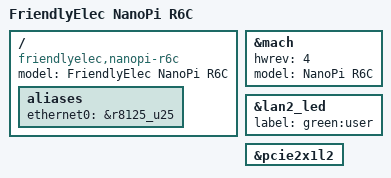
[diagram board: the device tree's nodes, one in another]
// SPDX-License-Identifier: (GPL-2.0+ OR MIT)
/*
 * Copyright (c) 2023 FriendlyElec Computer Tech. Co., Ltd.
 * (http://www.friendlyelec.com)
 *
 * Copyright (c) 2021 Rockchip Electronics Co., Ltd.
 */

/dts-v1/;

#include "rk3588-nanopi-r6s.dts"

/ {
	model = "FriendlyElec NanoPi R6C";
	compatible = "friendlyelec,nanopi-r6c", "rockchip,rk3588";

	aliases {
		ethernet0 = &r8125_u25;
	};
};

&mach {
	hwrev = <4>;
	model = "NanoPi R6C";
};

&lan2_led {
	label = "green:user";
};

&pcie2x1l2 {
	/delete-node/ pcie@40;
};
